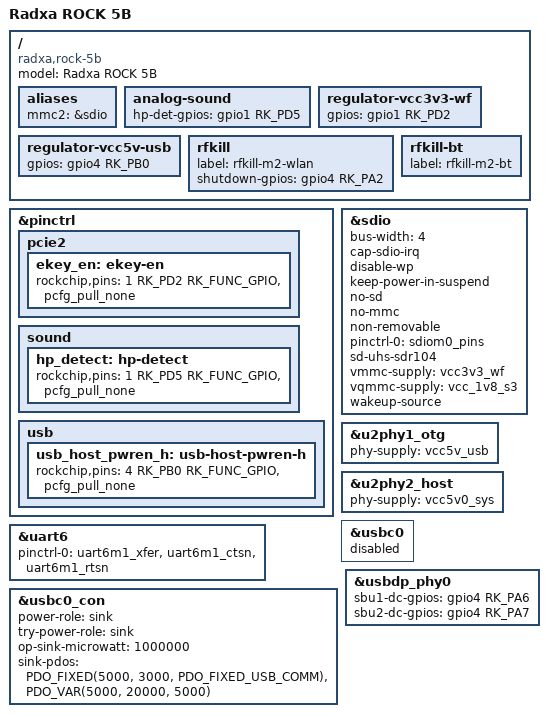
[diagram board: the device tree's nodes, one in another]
// SPDX-License-Identifier: (GPL-2.0+ OR MIT)
/*
 * Copyright (c) 2024 Radxa Computer (Shenzhen) Co., Ltd.
 */

/dts-v1/;

#include "rk3588-rock-5.dtsi"

/delete-node/ &vbus_typec0;
/delete-node/ &vcc_5v;
/delete-node/ &typec5v_pwren_h;

/ {
	model = "Radxa ROCK 5B";
	compatible = "radxa,rock-5b", "rockchip,rk3588";

	aliases {
		mmc2 = &sdio;
	};

	analog-sound {
		hp-det-gpios = <&gpio1 RK_PD5 GPIO_ACTIVE_HIGH>;
	};

	regulator-vcc3v3-wf {
		gpios = <&gpio1 RK_PD2 GPIO_ACTIVE_HIGH>;
	};

	regulator-vcc5v-usb {
		gpios = <&gpio4 RK_PB0 GPIO_ACTIVE_HIGH>;
	};

	rfkill {
		label = "rfkill-m2-wlan";
		shutdown-gpios = <&gpio4 RK_PA2 GPIO_ACTIVE_HIGH>;
	};

	rfkill-bt {
		label = "rfkill-m2-bt";
	};
};

&pinctrl {
	pcie2 {
		ekey_en: ekey-en {
			rockchip,pins = <1 RK_PD2 RK_FUNC_GPIO &pcfg_pull_none>;
		};
	};

	sound {
		hp_detect: hp-detect {
			rockchip,pins = <1 RK_PD5 RK_FUNC_GPIO &pcfg_pull_none>;
		};
	};

	usb {
		usb_host_pwren_h: usb-host-pwren-h {
			rockchip,pins = <4 RK_PB0 RK_FUNC_GPIO &pcfg_pull_none>;
		};
	};
};

&sdio {
	bus-width = <4>;
	cap-sdio-irq;
	disable-wp;
	keep-power-in-suspend;
	no-sd;
	no-mmc;
	non-removable;
	pinctrl-names = "default";
	pinctrl-0 = <&sdiom0_pins>;
	sd-uhs-sdr104;
	vmmc-supply = <&vcc3v3_wf>;
	vqmmc-supply = <&vcc_1v8_s3>;
	wakeup-source;
	status = "okay";
};

&u2phy1_otg {
	phy-supply = <&vcc5v_usb>;
};

&u2phy2_host {
	/* connected to USB hub, which is powered by vcc5v0_sys */
	phy-supply = <&vcc5v0_sys>;
};

&uart6 {
	pinctrl-names = "default";
	pinctrl-0 = <&uart6m1_xfer &uart6m1_ctsn &uart6m1_rtsn>;
	status = "okay";
};

&usbc0 {
	/*
	 * When the board is starting to send power-delivery messages
	 * too late (5 seconds according to the specification), the
	 * power-supply reacts with a hard-reset. That removes the
	 * power from VBUS for some time, which resets the whole board.
	 */
	status = "fail";
};

&usbc0_con {
	power-role = "sink";
	try-power-role = "sink";
	op-sink-microwatt = <1000000>;
	sink-pdos =
		<PDO_FIXED(5000, 3000, PDO_FIXED_USB_COMM)>,
		<PDO_VAR(5000, 20000, 5000)>;
};

&usbdp_phy0 {
	sbu1-dc-gpios = <&gpio4 RK_PA6 GPIO_ACTIVE_HIGH>;
	sbu2-dc-gpios = <&gpio4 RK_PA7 GPIO_ACTIVE_HIGH>;
};
